AUTOSAR XML (schema 00051)
package /Components
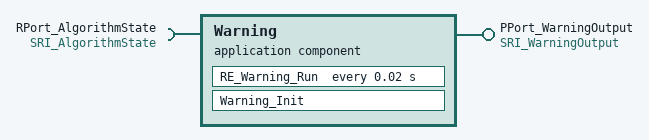
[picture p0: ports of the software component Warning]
  application sw component type Warning
    require port RPort_AlgorithmState: required-interface=SRI_AlgorithmState
      required-com-specs:
        data-element=BSD_State_Right, init-value=BSD_CLEAR
        data-element=BSD_State_Left, init-value=BSD_CLEAR
    provide port PPort_WarningOutput: provided-interface=SRI_WarningOutput
      provided-com-specs:
        data-element=LED_Right, init-value=LED_OFF
        data-element=LED_Left, init-value=LED_OFF
        data-element=Warning_State_Left, init-value=BSD_CLEAR
        data-element=Warning_State_Right, init-value=BSD_CLEAR
    behavior Warning_IB: handle-termination-and-restart=NO-SUPPORT
      timing event TE_Warning_20ms: start-on-event=RE_Warning_Run, period=0.02
      runnable Warning_Init
      runnable RE_Warning_Run: symbol=Warning_Step
        data-read-access:
          access IN_RPort_AlgorithmState_BSD_State_Right: accessed-variable=RPort_AlgorithmState.BSD_State_Right
          access IN_RPort_AlgorithmState_BSD_State_Left: accessed-variable=RPort_AlgorithmState.BSD_State_Left
        data-write-access:
          4 x access:
            OUT_PPort_WarningOutput_LED_Right: accessed-variable=PPort_WarningOutput.LED_Right
            OUT_PPort_WarningOutput_LED_Left: accessed-variable=PPort_WarningOutput.LED_Left
            OUT_PPort_WarningOutput_Warning_State_Left: accessed-variable=PPort_WarningOutput.Warning_State_Left
            OUT_PPort_WarningOutput_Warning_State_Right: accessed-variable=PPort_WarningOutput.Warning_State_Right
